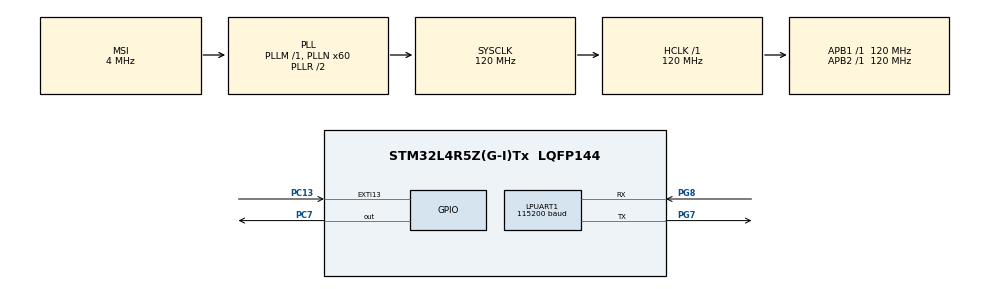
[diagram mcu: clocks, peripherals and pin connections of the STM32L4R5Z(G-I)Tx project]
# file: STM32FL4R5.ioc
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LPUART1.BaudRate=115200
LPUART1.WordLength=UART_WORDLENGTH_8B
Mcu.Family=STM32L4
Mcu.Name=STM32L4R5Z(G-I)Tx
Mcu.Package=LQFP144
NVIC.PriorityGroup=NVIC_PRIORITYGROUP_4
PA13\ (JTMS/SWDIO).Mode=Serial_Wire
PA13\ (JTMS/SWDIO).Signal=SYS_JTMS-SWDIO
PA14\ (JTCK/SWCLK).Mode=Serial_Wire
PA14\ (JTCK/SWCLK).Signal=SYS_JTCK-SWCLK
PC13.Signal=GPXTI13
PC7.GPIO_Speed=GPIO_SPEED_FREQ_VERY_HIGH
PC7.Signal=GPIO_Output
PG7.Mode=Asynchronous
PG7.Signal=LPUART1_TX
PG8.Mode=Asynchronous
PG8.Signal=LPUART1_RX
ProjectManager.HeapSize=0x200
ProjectManager.StackSize=0x400
ProjectManager.TargetToolchain=Makefile
RCC.AHBFreq_Value=120000000
RCC.APB1Freq_Value=120000000
RCC.APB1TimFreq_Value=120000000
RCC.APB2Freq_Value=120000000
RCC.APB2TimFreq_Value=120000000
RCC.CortexFreq_Value=120000000
RCC.HCLKFreq_Value=120000000
RCC.HSE_VALUE=8000000
RCC.HSI48_VALUE=48000000
RCC.HSI_VALUE=16000000
RCC.LSE_VALUE=32768
RCC.MSI_VALUE=4000000
RCC.PLLN=60
RCC.SYSCLKFreq_VALUE=120000000
RCC.SYSCLKSource=RCC_SYSCLKSOURCE_PLLCLK
RCC.VCOOutputFreq_Value=240000000
board=GPIO_EXTI

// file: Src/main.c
/* USER CODE BEGIN Header */
/**
  ******************************************************************************
  * @file           : main.c
  * @brief          : Main program body
  ******************************************************************************
  * @attention
  *
  * Copyright (c) 2022 STMicroelectronics.
  * All rights reserved.
  *
  * This software is licensed under terms that can be found in the LICENSE file
  * in the root directory of this software component.
  * If no LICENSE file comes with this software, it is provided AS-IS.
  *
  ******************************************************************************
  */
/* USER CODE END Header */
#include "main.h"
#include <stdint.h>
#include <stdio.h>

UART_HandleTypeDef hlpuart1;

void SystemClock_Config(void);
static void MX_GPIO_Init(void);
static void MX_LPUART1_UART_Init(void);

int main(void)
{

  /* MCU Configuration--------------------------------------------------------*/

  /* Reset of all peripherals, Initializes the Flash interface and the Systick. */
  HAL_Init();

  /* Configure the system clock */
  SystemClock_Config();

  /* Initialize all configured peripherals */
  MX_GPIO_Init();
  MX_LPUART1_UART_Init();
  /* USER CODE BEGIN 2 */
    printf("L4R5ZI Applicaion Started\r\n");
  /* USER CODE END 2 */

  /* Infinite loop */
  /* USER CODE BEGIN WHILE */
  while (1)
  {
   static uint64_t count;
    /* USER CODE END WHILE */

    /* USER CODE BEGIN 3 */
    count++;
    HAL_GPIO_WritePin(GPIOC, GPIO_PIN_7, count%2);

    printf("Tick Elapsed  : %d\r\n", HAL_GetTick()) ;
  }
  /* USER CODE END 3 */
}

int _write(int file, char *ptr, int len)
{
    HAL_UART_Transmit(&hlpuart1, (const uint8_t *)ptr, len, HAL_MAX_DELAY);
}

void SystemClock_Config(void)
{
  RCC_OscInitTypeDef RCC_OscInitStruct = {0};
  RCC_ClkInitTypeDef RCC_ClkInitStruct = {0};

  /** Configure the main internal regulator output voltage
  */
  if (HAL_PWREx_ControlVoltageScaling(PWR_REGULATOR_VOLTAGE_SCALE1_BOOST) != HAL_OK)
  {
    Error_Handler();
  }

  /** Initializes the RCC Oscillators according to the specified parameters
  * in the RCC_OscInitTypeDef structure.
  */
  RCC_OscInitStruct.OscillatorType = RCC_OSCILLATORTYPE_MSI;
  RCC_OscInitStruct.MSIState = RCC_MSI_ON;
  RCC_OscInitStruct.MSICalibrationValue = 0;
  RCC_OscInitStruct.MSIClockRange = RCC_MSIRANGE_6;
  RCC_OscInitStruct.PLL.PLLState = RCC_PLL_ON;
  RCC_OscInitStruct.PLL.PLLSource = RCC_PLLSOURCE_MSI;
  RCC_OscInitStruct.PLL.PLLM = 1;
  RCC_OscInitStruct.PLL.PLLN = 60;
  RCC_OscInitStruct.PLL.PLLP = RCC_PLLP_DIV2;
  RCC_OscInitStruct.PLL.PLLQ = RCC_PLLQ_DIV2;
  RCC_OscInitStruct.PLL.PLLR = RCC_PLLR_DIV2;
  if (HAL_RCC_OscConfig(&RCC_OscInitStruct) != HAL_OK)
  {
    Error_Handler();
  }

  /** Initializes the CPU, AHB and APB buses clocks
  */
  RCC_ClkInitStruct.ClockType = RCC_CLOCKTYPE_HCLK|RCC_CLOCKTYPE_SYSCLK
                              |RCC_CLOCKTYPE_PCLK1|RCC_CLOCKTYPE_PCLK2;
  RCC_ClkInitStruct.SYSCLKSource = RCC_SYSCLKSOURCE_PLLCLK;
  RCC_ClkInitStruct.AHBCLKDivider = RCC_SYSCLK_DIV1;
  RCC_ClkInitStruct.APB1CLKDivider = RCC_HCLK_DIV1;
  RCC_ClkInitStruct.APB2CLKDivider = RCC_HCLK_DIV1;

  if (HAL_RCC_ClockConfig(&RCC_ClkInitStruct, FLASH_LATENCY_5) != HAL_OK)
  {
    Error_Handler();
  }
}

static void MX_LPUART1_UART_Init(void)
{

  hlpuart1.Instance = LPUART1;
  hlpuart1.Init.BaudRate = 115200;
  hlpuart1.Init.WordLength = UART_WORDLENGTH_8B;
  hlpuart1.Init.StopBits = UART_STOPBITS_1;
  hlpuart1.Init.Parity = UART_PARITY_NONE;
  hlpuart1.Init.Mode = UART_MODE_TX_RX;
  hlpuart1.Init.HwFlowCtl = UART_HWCONTROL_NONE;
  hlpuart1.Init.OneBitSampling = UART_ONE_BIT_SAMPLE_DISABLE;
  hlpuart1.Init.ClockPrescaler = UART_PRESCALER_DIV1;
  hlpuart1.AdvancedInit.AdvFeatureInit = UART_ADVFEATURE_NO_INIT;
  hlpuart1.FifoMode = UART_FIFOMODE_DISABLE;
  if (HAL_UART_Init(&hlpuart1) != HAL_OK)
  {
    Error_Handler();
  }
  if (HAL_UARTEx_SetTxFifoThreshold(&hlpuart1, UART_TXFIFO_THRESHOLD_1_8) != HAL_OK)
  {
    Error_Handler();
  }
  if (HAL_UARTEx_SetRxFifoThreshold(&hlpuart1, UART_RXFIFO_THRESHOLD_1_8) != HAL_OK)
  {
    Error_Handler();
  }
  if (HAL_UARTEx_DisableFifoMode(&hlpuart1) != HAL_OK)
  {
    Error_Handler();
  }

}

static void MX_GPIO_Init(void)
{
  GPIO_InitTypeDef GPIO_InitStruct = {0};

  /* GPIO Ports Clock Enable */
  __HAL_RCC_GPIOC_CLK_ENABLE();
  __HAL_RCC_GPIOG_CLK_ENABLE();
  HAL_PWREx_EnableVddIO2();
  __HAL_RCC_GPIOA_CLK_ENABLE();

  /*Configure GPIO pin Output Level */
  HAL_GPIO_WritePin(GPIOC, GPIO_PIN_7, GPIO_PIN_RESET);

  /*Configure GPIO pin : PC13 */
  GPIO_InitStruct.Pin = GPIO_PIN_13;
  GPIO_InitStruct.Mode = GPIO_MODE_IT_RISING;
  GPIO_InitStruct.Pull = GPIO_NOPULL;
  HAL_GPIO_Init(GPIOC, &GPIO_InitStruct);

  /*Configure GPIO pin : PC7 */
  GPIO_InitStruct.Pin = GPIO_PIN_7;
  GPIO_InitStruct.Mode = GPIO_MODE_OUTPUT_PP;
  GPIO_InitStruct.Pull = GPIO_NOPULL;
  GPIO_InitStruct.Speed = GPIO_SPEED_FREQ_VERY_HIGH;
  HAL_GPIO_Init(GPIOC, &GPIO_InitStruct);

}

void Error_Handler(void)
{
  __disable_irq();
  while (1)
  {
  }
}
